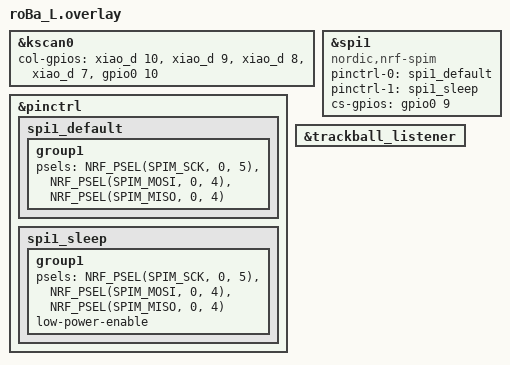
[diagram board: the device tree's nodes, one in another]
#include "roBa.dtsi"

&kscan0 {
        col-gpios
            = <&xiao_d 10 GPIO_ACTIVE_HIGH>
            , <&xiao_d 9 GPIO_ACTIVE_HIGH> 
            , <&xiao_d 8 GPIO_ACTIVE_HIGH> 
            , <&xiao_d 7 GPIO_ACTIVE_HIGH> 
            , <&gpio0 10 GPIO_ACTIVE_HIGH>
            ;
};


&pinctrl {
	spi1_default: spi1_default {
		group1 {
			psels = <NRF_PSEL(SPIM_SCK, 0, 5)>,
				<NRF_PSEL(SPIM_MOSI, 0, 4)>,
				<NRF_PSEL(SPIM_MISO, 0, 4)>;
		};
	};
	spi1_sleep: spi1_sleep {
		group1 {
			psels = <NRF_PSEL(SPIM_SCK, 0, 5)>,
				<NRF_PSEL(SPIM_MOSI, 0, 4)>,
				<NRF_PSEL(SPIM_MISO, 0, 4)>;
			low-power-enable;
		};
	};	
};


nice_view_spi: &spi1 {
	compatible = "nordic,nrf-spim";
	pinctrl-0 = <&spi1_default>;
	pinctrl-1 = <&spi1_sleep>;
	pinctrl-names = "default", "sleep";
	cs-gpios = <&gpio0 9 GPIO_ACTIVE_HIGH>;
};


&trackball_listener {
    status = "okay";
};

